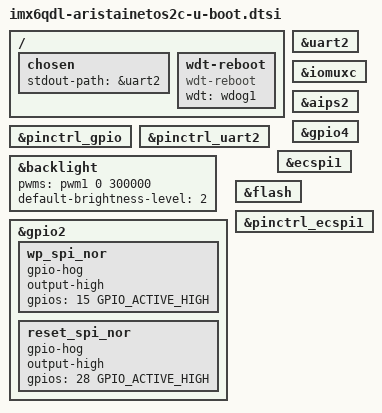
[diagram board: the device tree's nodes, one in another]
// SPDX-License-Identifier: GPL-2.0+ or X11
/*
 * Copyright (C) 2019 Heiko Schocher <hs@denx.de>
 */

/ {
	chosen {
		u-boot,dm-all;
		stdout-path = &uart2;
	};

	wdt-reboot {
		compatible = "wdt-reboot";
		wdt = <&wdog1>;
	};
};

&uart2 {
	u-boot,dm-all;
};

&pinctrl_gpio {
	u-boot,dm-all;
};

&pinctrl_uart2 {
	u-boot,dm-all;
};

&iomuxc {
	u-boot,dm-all;
};

&aips2 {
	u-boot,dm-all;
};

&backlight {
	pwms = <&pwm1 0 300000>;
	default-brightness-level = <2>;
};

/*
 * allow switching write protect / reset pin by gpio,
 * because "pinctrl-assert-gpios" from &ecspi1 isn't handled by u-boot
 */
&gpio2 {
	u-boot,dm-all;

	wp_spi_nor {
		gpio-hog;
		output-high;
		gpios = <15 GPIO_ACTIVE_HIGH>;
	};

	reset_spi_nor {
		gpio-hog;
		output-high;
		gpios = <28 GPIO_ACTIVE_HIGH>;
	};
};

&gpio4 {
	u-boot,dm-all;
};

&ecspi1 {
	u-boot,dm-all;
};

&flash {
	u-boot,dm-all;
};

&pinctrl_ecspi1 {
	u-boot,dm-all;
};
